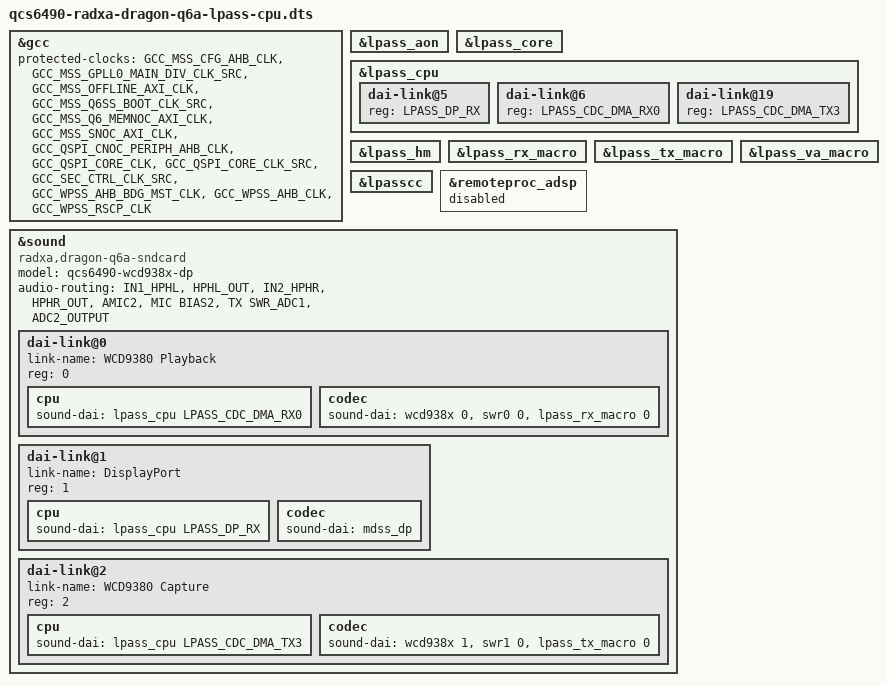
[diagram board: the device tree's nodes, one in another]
// SPDX-License-Identifier: BSD-3-Clause
/*
 * Copyright (c) 2025-2026 Radxa Computer (Shenzhen) Co., Ltd.
 *
 * Direct CPU access to the LPASS hardware block on this platform is
 * restricted by default. Booting the Linux kernel in EL2 will allow the
 * kernel to access the LPASS hardware directly.
 *
 * You can achieve this by setting the Hypervisor Override BIOS setting to
 * "Enabled" if you are using the official UEFI firmware.
 */

/dts-v1/;

#include "qcs6490-radxa-dragon-q6a.dtsi"

&gcc {
	protected-clocks = <GCC_MSS_CFG_AHB_CLK>,
			   <GCC_MSS_GPLL0_MAIN_DIV_CLK_SRC>,
			   <GCC_MSS_OFFLINE_AXI_CLK>,
			   <GCC_MSS_Q6SS_BOOT_CLK_SRC>,
			   <GCC_MSS_Q6_MEMNOC_AXI_CLK>,
			   <GCC_MSS_SNOC_AXI_CLK>,
			   <GCC_QSPI_CNOC_PERIPH_AHB_CLK>,
			   <GCC_QSPI_CORE_CLK>,
			   <GCC_QSPI_CORE_CLK_SRC>,
			   <GCC_SEC_CTRL_CLK_SRC>,
			   <GCC_WPSS_AHB_BDG_MST_CLK>,
			   <GCC_WPSS_AHB_CLK>,
			   <GCC_WPSS_RSCP_CLK>;
};

&lpass_aon {
	status = "okay";
};

&lpass_core {
	status = "okay";
};

&lpass_cpu {
	status = "okay";

	dai-link@5 {
		reg = <LPASS_DP_RX>;
	};

	dai-link@6 {
		reg = <LPASS_CDC_DMA_RX0>;
	};

	dai-link@19 {
		reg = <LPASS_CDC_DMA_TX3>;
	};
};

&lpass_hm {
	status = "okay";
};

&lpass_rx_macro {
	status = "okay";
};

&lpass_tx_macro {
	status = "okay";
};

&lpass_va_macro {
	status = "okay";
};

&lpasscc {
	status = "okay";
};

&remoteproc_adsp {
	status = "disabled";
};

&sound {
	compatible = "radxa,dragon-q6a-sndcard", "google,sc7280-herobrine";
	model = "qcs6490-wcd938x-dp";

	audio-routing = "IN1_HPHL", "HPHL_OUT",
			"IN2_HPHR", "HPHR_OUT",
			"AMIC2", "MIC BIAS2",
			"TX SWR_ADC1", "ADC2_OUTPUT";

	#address-cells = <1>;
	#size-cells = <0>;

	dai-link@0 {
		link-name = "WCD9380 Playback";
		reg = <0>;

		cpu {
			sound-dai = <&lpass_cpu LPASS_CDC_DMA_RX0>;
		};

		codec {
			sound-dai = <&wcd938x 0>, <&swr0 0>, <&lpass_rx_macro 0>;
		};
	};

	dai-link@1 {
		link-name = "DisplayPort";
		reg = <1>;

		cpu {
			sound-dai = <&lpass_cpu LPASS_DP_RX>;
		};

		codec {
			sound-dai = <&mdss_dp>;
		};
	};

	dai-link@2 {
		link-name = "WCD9380 Capture";
		reg = <2>;

		cpu {
			sound-dai = <&lpass_cpu LPASS_CDC_DMA_TX3>;
		};

		codec {
			sound-dai = <&wcd938x 1>, <&swr1 0>, <&lpass_tx_macro 0>;
		};
	};
};
